# RA register map
Vendor: Renesas; Series: All Chips; File version: x.xx
Registers are 32-bit, read-write, reset 0x0 unless marked. A register's access mark holds for its fields unless they carry their own. Offsets are from the block's base; [hi:lo] are bit positions; 'fields as' and 'values as' point back to an identical list; <NAME> marks a mode.

## OSM — Option Setting Memory
Base 0x00000400
0x00 OFS0 read reset not defined — Option Function Select Register 0
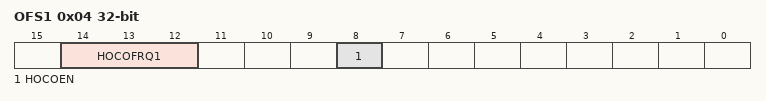
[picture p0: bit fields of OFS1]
0x04 OFS1 read reset not defined — Option Function Select Register 1
  [14:12] HOCOFRQ1 — HOCO Frequency Setting 1
    0=24 MHz; 0b2=32 MHz; 0b4=48 MHz; 0b5=64 MHz
  [8] HOCOEN — HOCO Oscillation Enable
    0=Disabled; 1=Enabled

## R_ACMPHS0 — High-Speed Analog Comparator
Base 0x40085000
Same registers: R_ACMPHS1 0x40085100, R_ACMPHS2 0x40085200, R_ACMPHS3 0x40085300, R_ACMPHS4 0x40085400, R_ACMPHS5 0x40085500
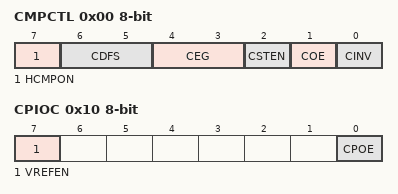
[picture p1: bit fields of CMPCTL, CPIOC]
0x00 CMPCTL 8-bit — Comparator Control Register
  [7] HCMPON — Comparator operation control
    0=Operation stopped (the comparator outputs a low-level signal); 1=Operation enabled (input to the comparator pins is enabled
  [6:5] CDFS — Noise filter selection
    0=Noise filter not used; 1=Noise filter sampling frequency is 2^3/PCLKB; 2=Noise filter sampling frequency is 2^4/PCLKB; 3=Noise filter sampling frequency is 2^5/PCLKB
  [4:3] CEG — Selection of valid edge (Edge selector)
    0=No edge selection; 1=Rising edge selection; 2=Falling edge selection; 3=Both-edge selection
  [2] CSTEN — Interrupt Select
    0=Output via the Edge selector; 1=Direct output
  [1] COE — Comparator output enable
    0=Comparator output disabled (the output signal is low level); 1=Comparator output enabled
  [0] CINV — Comparator output polarity selection
    0=Comparator output not inverted; 1=Comparator output inverted
0x04 CMPSEL0 8-bit — Comparator Input Select Register
  [3:0] CMPSEL — Comparator Input Selection
    0=Do not input; 1=Select IVCMP0; 2=Select IVCMP1; 4=Select IVCMP2; 8=Select IVCMP3
0x08 CMPSEL1 8-bit — Comparator Reference Voltage Select Register
  [5:0] CRVS — Reference Voltage Selection
    0=Do not input; 1=Select IVREF0; 2=Select IVREF1; 4=Select IVREF2; 8=Select IVREF3
0x0C CMPMON 8-bit ro — Comparator Output Monitor Register
  [0] CMPMON — Comparator output monitor
    0=Comparator output Low; 1=Comparator output High
0x10 CPIOC 8-bit — Comparator Output Control Register
  [7] VREFEN — Internal Vref enable
    0=Internal Vref disable; 1=Internal Vref enable
  [0] CPOE — Comparator output selection
    0=VCOUT pin output of the comparator is disabled (the output signal is low level); 1=VCOUT pin output of the comparator is enabled

## R_ACMPLP — Low-Power Analog Comparator
Base 0x40085E00
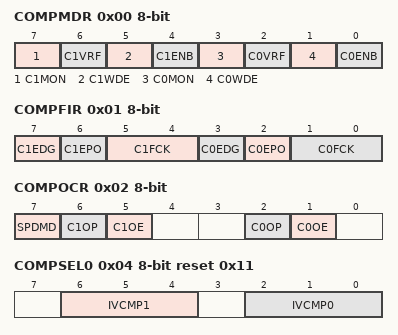
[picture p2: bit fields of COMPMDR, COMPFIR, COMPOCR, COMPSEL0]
0x00 COMPMDR 8-bit — ACMPLP Mode Setting Register
  [7] C1MON ro — ACMPLP1 Monitor Flag
    0=CMPIN1 < CMPREF1, CMPIN1 < internal reference voltage, or ACMPLP1 operation disabled.(When the window function is disabled)/CMPIN1 < VRFL, CMPIN1 > VRFH, or ACMPLP1 operation disabled.(When the window function is enabled); 1=CMPIN1 > CMPREF1, or CMPIN1 > internal reference voltage.(When the window function is disabled)/VRFL < CMPIN1 < VRFH.(When the window function is enabled)
  [6] C1VRF — ACMPLP1 Reference Voltage Selection
    0=Select CMPREF1 input as ACMPLP1 reference voltage; 1=Select internal reference voltage (Vref) as ACMPLP1 reference voltage
  [5] C1WDE — ACMPLP1 Window Function Mode Enable
    0=Disabled; 1=Enabled
  [4] C1ENB — ACMPLP1 Operation Enable
    0=Disabled; 1=Enabled
  [3] C0MON ro — ACMPLP0 Monitor Flag
    0=CMPIN0 < CMPREF0, CMPIN0 < internal reference voltage, or ACMPLP0 operation disabled.(When the window function is disabled)/CMPIN0 < VRFL, CMPIN0 > VRFH, or ACMPLP0 operation disabled.(When the window function is enabled); 1=CMPIN0 > CMPREF0, or CMPIN0 > internal reference voltage.(When the window function is disabled)/VRFL < CMPIN0 < VRFH.(When the window function is enabled)
  [2] C0VRF — ACMPLP0 Reference Voltage Selection
    0=Select CMPREF0 input as ACMPLP0 reference voltage; 1=Select internal reference voltage (Vref) as ACMPLP0 reference voltage
  [1] C0WDE — ACMPLP0 Window Function Mode Enable
    0=Disabled; 1=Enabled
  [0] C0ENB — ACMPLP0 Operation Enable
    0=Disabled; 1=Enabled
0x01 COMPFIR 8-bit — ACMPLP Filter Control Register
  [7] C1EDG — ACMPLP1 Edge Detection Selection
    0=Interrupt and ELC event request by one-edge detection; 1=Interrupt and ELC event request by both-edge detection
  [6] C1EPO — ACMPLP1 Edge Polarity Switching
    0=Interrupt and ELC event request at rising edge; 1=Interrupt and ELC event request at falling edge
  [5:4] C1FCK — ACMPLP1 Filter Select
    0=No Sampling (bypass); 1=Sampling at PCLK; 2=Sampling at PCLK/8; 3=Sampling at PCLK/32
  [3] C0EDG — ACMPLP0 Edge Detection Selection
    values as C1EDG
  [2] C0EPO — ACMPLP0 Edge Polarity Switching
    values as C1EPO
  [1:0] C0FCK — ACMPLP0 Filter Select
    values as C1FCK
0x02 COMPOCR 8-bit — ACMPLP Output Control Register
  [7] SPDMD — ACMPLP0/ACMPLP1 Speed Selection
    0=Comparator low-speed mode; 1=Comparator high-speed mode
  [6] C1OP — ACMPLP1 VCOUT Output Polarity Selection
    0=Non inverted; 1=Inverted
  [5] C1OE — ACMPLP1 VCOUT Pin Output Enable
    0=Disabled; 1=Enabled
  [2] C0OP — ACMPLP0 VCOUT Output Polarity Selection
    0=Non inverted; 1=Inverted
  [1] C0OE — ACMPLP0 VCOUT Pin Output Enable
    0=Disabled; 1=Enabled
0x04 COMPSEL0 8-bit reset 0x11 — Comparator Input Select Register
  [6:4] IVCMP1 — ACMPLP1 Input (IVCMP1) Selection
    0=No input; 1=CMPIN1 input selected; 2=AMP1O output selected
  [2:0] IVCMP0 — ACMPLP0 Input (IVCMP0) Selection
    0=No input; 1=CMPIN0 input selected; 2=AMP0O output selected
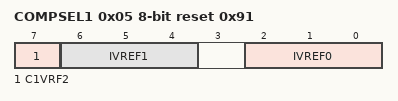
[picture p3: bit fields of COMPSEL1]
0x05 COMPSEL1 8-bit reset 0x91 — Comparator Reference voltage Select Register
  [7] C1VRF2 — ACMPLP1 Reference Voltage Selection
    0=IVREF0 selected; 1=IVREF1 selected
  [6:4] IVREF1 — ACMPLP1 Reference Voltage(IVREF1) Selection
    0=No reference voltage; 1=CMPREF1 selected; 2=DA8_1 output selected
  [2:0] IVREF0 — ACMPLP0 Reference Voltage (IVREF0) Selection
    0=No reference voltage; 1=CMPREF0 selected; 2=DA8_0 output selected
